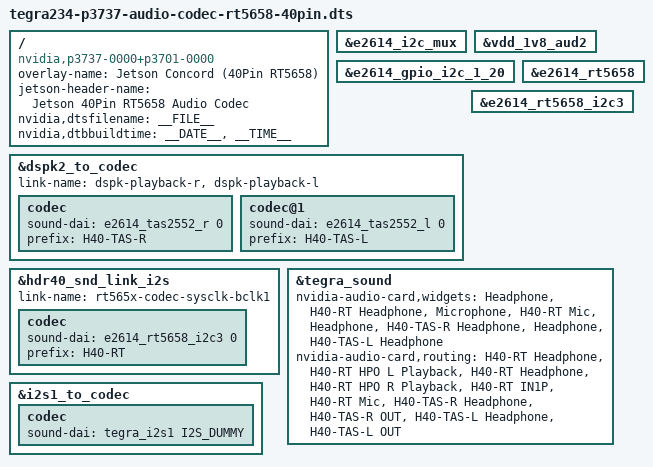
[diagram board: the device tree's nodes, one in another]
/*
 * Copyright (c) 2021, NVIDIA CORPORATION.  All rights reserved.
 *
 * This program is free software; you can redistribute it and/or modify it
 * under the terms and conditions of the GNU General Public License,
 * version 2, as published by the Free Software Foundation.
 *
 * This program is distributed in the hope it will be useful, but WITHOUT
 * ANY WARRANTY; without even the implied warranty of MERCHANTABILITY or
 * FITNESS FOR A PARTICULAR PURPOSE.  See the GNU General Public License for
 * more details.
 *
 * You should have received a copy of the GNU General Public License
 * along with this program.  If not, see <http://www.gnu.org/licenses/>.
 */

/*
 * Audio dts overlay for enabling I2S to RT5658 codec on CVB 40 Pin Header.
 */

#include <dt-bindings/gpio/tegra234-gpio.h>
#include <dt-bindings/sound/tegra-asoc-dais.h>

/dts-v1/;
/plugin/;

/ {
	overlay-name = "Jetson Concord (40Pin RT5658)";
	jetson-header-name = "Jetson 40Pin RT5658 Audio Codec";
	compatible = "nvidia,p3737-0000+p3701-0000";
	nvidia,dtsfilename = __FILE__;
	nvidia,dtbbuildtime = __DATE__, __TIME__;

	fragment@0 {
		target = <&e2614_i2c_mux>;

		board_config {
			ids = "2614-0000-*";
		};

		__overlay__ {
			status = "okay";
		};
	};

	fragment@1 {
		target = <&vdd_1v8_aud2>;

		board_config {
			ids = "2614-0000-*";
		};

		__overlay__ {
			status = "okay";
		};
	};

	fragment@2 {
	       target = <&e2614_gpio_i2c_1_20>;

		board_config {
			ids = "2614-0000-*";
		};

	       __overlay__ {
		       status = "okay";
	       };
	};

	fragment@3 {
		target = <&dspk2_to_codec>;

		board_config {
			ids = "2614-0000-*";
		};

		__overlay__ {
			link-name = "dspk-playback-r",
					"dspk-playback-l";

			codec {
				sound-dai = <&e2614_tas2552_r 0>;
				prefix = "H40-TAS-R";
			};

			codec@1 {
				sound-dai = <&e2614_tas2552_l 0>;
				prefix = "H40-TAS-L";
			};

		};
	};

	fragment@4 {
		target = <&e2614_rt5658>;

		board_config {
			ids = "2614-0000-000";
		};

		__overlay__ {
			status = "okay";
		};
	};

	fragment@5 {
		target = <&hdr40_snd_link_i2s>;

		board_config {
			ids = "2614-0000-000";
		};

		__overlay__ {
			link-name = "rt565x-codec-sysclk-bclk1";
			codec {
				sound-dai = <&e2614_rt5658 0>;
				prefix = "H40-RT";
			};
		};
	};

	fragment@6 {
		target = <&hdr40_snd_link_i2s>;

		board_config {
			ids = "2614-0000-100";
		};

		__overlay__ {
			link-name = "rt565x-codec-sysclk-bclk1";
			codec {
				sound-dai = <&e2614_rt5658_i2c3 0>;
				prefix = "H40-RT";
			};
		};
	};

	fragment@7 {
		target = <&e2614_rt5658_i2c3>;

		board_config {
			ids = "2614-0000-100";
		};

		__overlay__ {
			status = "okay";
		};
	};

	fragment@8 {
		target = <&tegra_sound>;

		board_config {
			ids = "2614-0000-*";
		};

		__overlay__ {
			nvidia-audio-card,widgets =
				"Headphone",    "H40-RT Headphone",
				"Microphone",   "H40-RT Mic",
				"Headphone",    "H40-TAS-R Headphone",
				"Headphone",    "H40-TAS-L Headphone";

			nvidia-audio-card,routing =
				"H40-RT Headphone",             "H40-RT HPO L Playback",
				"H40-RT Headphone",             "H40-RT HPO R Playback",
				"H40-RT IN1P",                  "H40-RT Mic",
				"H40-TAS-R Headphone",          "H40-TAS-R OUT",
				"H40-TAS-L Headphone",          "H40-TAS-L OUT";
		};
	};

	fragment@9 {
		target = <&i2s1_to_codec>;

		board_config {
			ids = "2614-0000-*";
		};

		__overlay__ {
			codec {
				sound-dai = <&tegra_i2s1 I2S_DUMMY>;
			};
		};
	};
};
